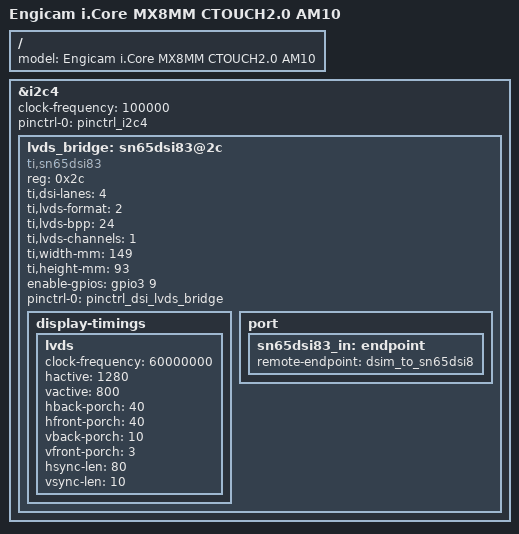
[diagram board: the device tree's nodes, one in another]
/*
 * Copyright 2020 Engicam srl
 * Copyright 2018 NXP
 *
 * This program is free software; you can redistribute it and/or
 * modify it under the terms of the GNU General Public License
 * as published by the Free Software Foundation; either version 2
 * of the License, or (at your option) any later version.
 *
 * This program is distributed in the hope that it will be useful,
 * but WITHOUT ANY WARRANTY; without even the implied warranty of
 * MERCHANTABILITY or FITNESS FOR A PARTICULAR PURPOSE.  See the
 * GNU General Public License for more details.
 */

#include "imx8mm-icore-ctouch2.dts"

/ {
	model = "Engicam i.Core MX8MM CTOUCH2.0 AM10";
};

&i2c4 {
  clock-frequency = <100000>;
  pinctrl-names = "default";
  pinctrl-0 = <&pinctrl_i2c4>;
  status = "okay";

  lvds_bridge: sn65dsi83@2c {
    compatible = "ti,sn65dsi83";
    reg = <0x2c>;
    ti,dsi-lanes = <4>;
    ti,lvds-format = <2>;
    ti,lvds-bpp = <24>;
    ti,lvds-channels = <1>;
    ti,width-mm = <149>;
    ti,height-mm = <93>;
    enable-gpios = <&gpio3 9  GPIO_ACTIVE_HIGH>;
    pinctrl-names = "default";
    pinctrl-0 = <&pinctrl_dsi_lvds_bridge>;
    status = "okay";

    display-timings {
      lvds {
        clock-frequency = <60000000>;
        hactive = <1280>;
        vactive = <800>;
        hback-porch = <40>;
        hfront-porch = <40>;
        vback-porch = <10>;
        vfront-porch = <3>;
        hsync-len = <80>;
        vsync-len = <10>;
      };
    };

    port {
      sn65dsi83_in: endpoint {
        remote-endpoint = <&dsim_to_sn65dsi8>;
      };
    };
  };
};
